# 3065PNPIMH register map
File version: 1.0
Registers are 32-bit, access per field, reset 0x0 unless marked. A register's access mark holds for its fields unless they carry their own. Offsets are from the block's base; [hi:lo] are bit positions.

## GPT0 — GPT0 peripheral interface
Base 0x14700000
Same registers: GPT1 0x14701000, GPT2 0x14702000, GPT3 0x14703000
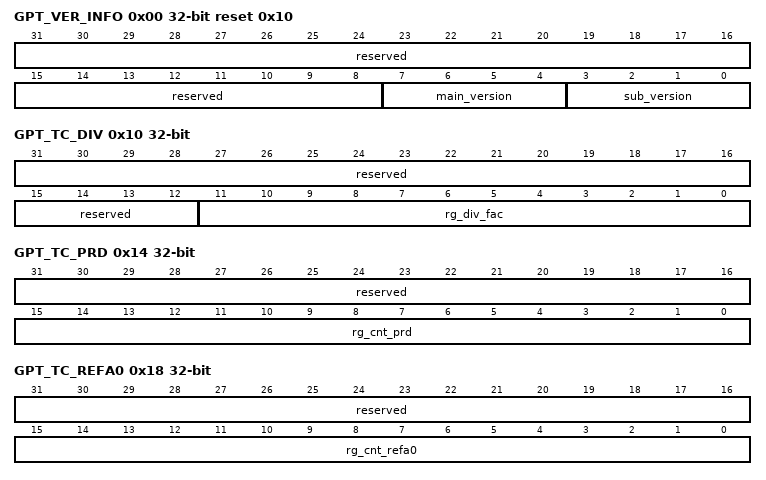
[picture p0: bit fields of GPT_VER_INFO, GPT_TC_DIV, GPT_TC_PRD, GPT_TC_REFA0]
0x00 GPT_VER_INFO ro reset 0x10 — GPT_VER_INFO为版本信息寄存器。
  [31:8] reserved — 保留。
  [7:4] main_version — 主版本号
  [3:0] sub_version — 子版本号
0x10 GPT_TC_DIV — GPT_TC_DIV为分频系数寄存器。
  [31:12] reserved ro — 保留。
  [11:0] rg_div_fac rw — 分频系数。 分频倍数=分频系数+1。
0x14 GPT_TC_PRD — GPT_TC_PRD为计数周期寄存器。
  [31:16] reserved ro — 保留。
  [15:0] rg_cnt_prd rw — 时基计数器（TCCNT）的计数周期。
0x18 GPT_TC_REFA0 — GPT_TC_REFA0为计数参考值A0寄存器。
  [31:16] reserved ro — 保留。
  [15:0] rg_cnt_refa0 rw — 时基计数器（TCCNT）的参考值A0，应当小于或等于计数周期。
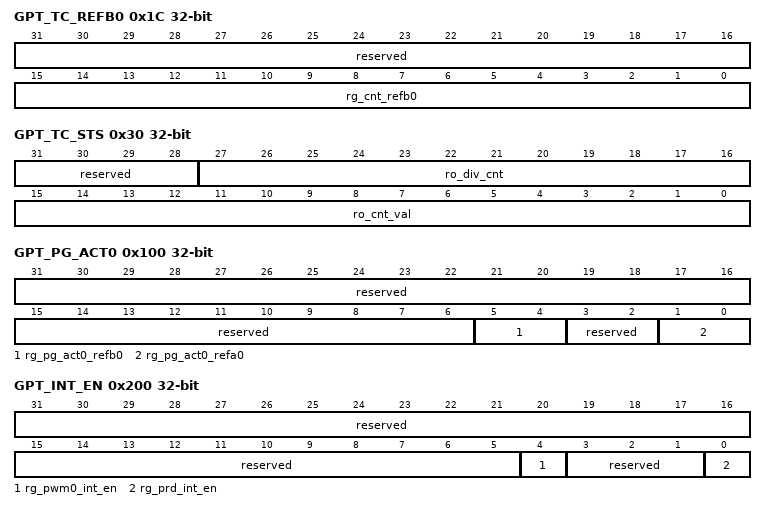
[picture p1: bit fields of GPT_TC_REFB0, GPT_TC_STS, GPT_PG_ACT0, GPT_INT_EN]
0x1C GPT_TC_REFB0 — GPT_TC_REFB0为计数参考值B0寄存器。
  [31:16] reserved ro — 保留。
  [15:0] rg_cnt_refb0 rw — 时基计数器（TCCNT）的参考值B0，应当小于或等于计数周期。
0x30 GPT_TC_STS ro — GPT_TC_STS为计数状态寄存器。
  [31:28] reserved — 保留。
  [27:16] ro_div_cnt — 分频计数器（DIVCNT）的当前计数值。
  [15:0] ro_cnt_val — 时基计数器（TCCNT）的当前计数值。
0x100 GPT_PG_ACT0 — GPT_PG_ACT0为通道0动作配置寄存器。
  [31:6] reserved ro — 保留。
  [5:4] rg_pg_act0_refb0 rw — 时基计数器（TCCNT）等于参考值B0时，通道0的PWM输出动作。 00：无影响； 01：置为低电平； 10：置为高电平； 11：翻转电平。
  [3:2] reserved ro — 保留。
  [1:0] rg_pg_act0_refa0 rw — 时基计数器（TCCNT）等于参考值A0时，通道0的PWM输出动作。 00：无影响； 01：置为低电平； 10：置为高电平； 11：翻转电平。
0x200 GPT_INT_EN — GPT_INT_EN为中断使能寄存器。
  [31:5] reserved ro — 保留。
  [4] rg_pwm0_int_en rw — 通道0输出完成中断的使能。 0：禁能； 1：使能。
  [3:1] reserved ro — 保留。
  [0] rg_prd_int_en rw — 周期中断的使能。 0：禁能； 1：使能。
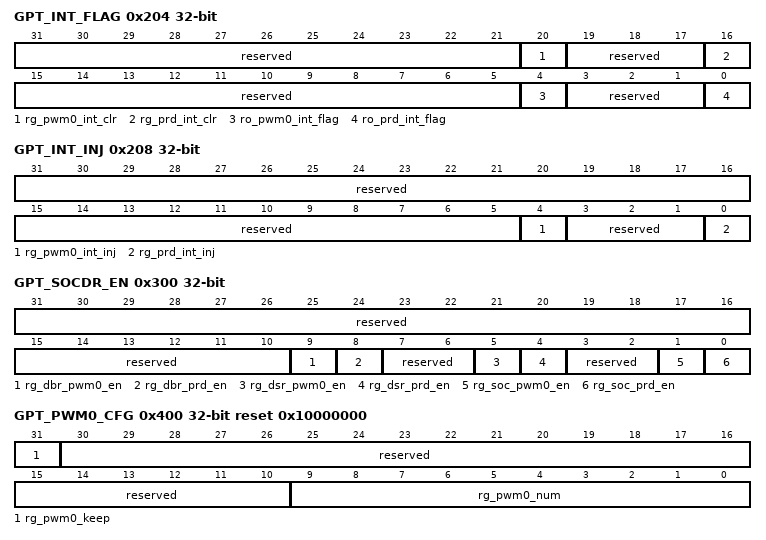
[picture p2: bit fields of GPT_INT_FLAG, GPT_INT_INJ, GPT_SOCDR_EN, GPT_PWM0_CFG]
0x204 GPT_INT_FLAG — GPT_INT_FLAG为中断标志寄存器。
  [31:21] reserved ro — 保留。
  [20] rg_pwm0_int_clr rw write-1-clears — 通道0输出完成中断的中断清除，写1清0。 0：写0无效； 1：写1有效。
  [19:17] reserved ro — 保留。
  [16] rg_prd_int_clr rw write-1-clears — 周期中断的中断清除，写1清0。 0：写0无效； 1：写1有效。
  [15:5] reserved ro — 保留。
  [4] ro_pwm0_int_flag ro — 通道0输出完成中断的中断标志。 0：通道0输出完成中断标志无效； 1：通道0输出完成中断标志有效。
  [3:1] reserved ro — 保留。
  [0] ro_prd_int_flag ro — 周期中断的中断标志。 0：周期中断标志无效； 1：周期中断标志有效。
0x208 GPT_INT_INJ — GPT_INT_INJ为中断注入寄存器。
  [31:5] reserved ro — 保留。
  [4] rg_pwm0_int_inj rw write-1-clears — 软件注入通道0输出完成中断，写1清0。 0：写0无效； 1：写1有效。
  [3:1] reserved ro — 保留。
  [0] rg_prd_int_inj rw write-1-clears — 软件注入周期中断，写1清0。 0：写0无效； 1：写1有效。
0x300 GPT_SOCDR_EN — GPT_SOCDR_EN为SOC/DMA请求使能寄存器。
  [31:10] reserved ro — 保留。
  [9] rg_dbr_pwm0_en rw — 通道0输出完成产生DMA Burst request信号的使能。 0：通道0输出完成时禁止产生DMA Burst request； 1：通道0输出完成时产生DMA Burst request信号。
  [8] rg_dbr_prd_en rw — 计数周期结束产生DMA Burst request信号的使能。 0：计数周期结束时禁止产生DMA Burst request； 1：计数周期结束时产生DMA Burst request信号。
  [7:6] reserved ro — 保留。
  [5] rg_dsr_pwm0_en rw — 通道0输出完成产生DMA Single request信号的使能。 0：通道0输出完成时禁止产生DMA Single request； 1：通道0输出完成时产生DMA Single request信号。
  [4] rg_dsr_prd_en rw — 计数周期结束产生DMA Single request信号的使能。 0：计数周期结束时禁止产生DMA Single request； 1：计数周期结束时产生DMA Single request信号。
  [3:2] reserved ro — 保留。
  [1] rg_soc_pwm0_en rw — 通道0输出完成产生SOC信号的使能。 0：通道0输出完成时禁止产生SOC信号； 1：通道0输出完成时产生SOC信号。
  [0] rg_soc_prd_en rw — 计数周期结束产生SOC信号的使能。 0：计数周期结束时禁止产生SOC信号； 1：计数周期结束时产生SOC信号。
0x400 GPT_PWM0_CFG reset 0x10000000 — GPT_PWM0_CFG为通道0配置寄存器。
  [31] rg_pwm0_keep rw — 通道0输出PWM的模式。 0：通道0输出有限个数PWM，输出个数由GPT_PWM0_CFG[rg_pwm0_num]配置； 1：通道0输出无限个数PWM。
  [30:10] reserved ro — 保留。
  [9:0] rg_pwm0_num rw — 通道0输出PWM的个数。 仅当GPT_PWM0_CFG[rg_pwm0_keep]为0时有效。
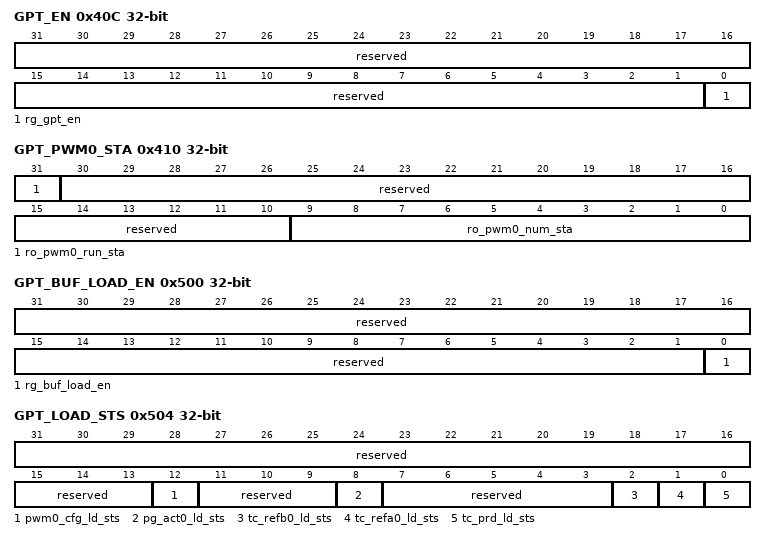
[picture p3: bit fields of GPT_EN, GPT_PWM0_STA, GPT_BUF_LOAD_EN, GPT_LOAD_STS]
0x40C GPT_EN — GPT_EN为GPT使能寄存器。
  [31:1] reserved ro — 保留。
  [0] rg_gpt_en rw — GPT使能控制。 0：GPT通道关闭； 1：GPT通道使能。
0x410 GPT_PWM0_STA ro — GPT_PWM0_STA为通道0状态寄存器。
  [31] ro_pwm0_run_sta — 通道0的输出状态。 0：表示目前通道0不在输出PWM波； 1：表示目前通道0正在输出PWM波。
  [30:10] reserved — 保留。
  [9:0] ro_pwm0_num_sta — 通道0输出PWM的个数。 当GPT_PWM0_CFG[rg_pwm0_keep]为1时，一直为0； 当GPT_PWM0_CFG[rg_pwm0_keep]为0时，GPT_PWM0_STA[ro_pwm0_num_sta]表示通道0正在输出第几个PWM波。
0x500 GPT_BUF_LOAD_EN — GPT_BUF_LOAD_EN为缓存加载使能寄存器。
  [31:1] reserved ro — 保留。
  [0] rg_buf_load_en rw — 支持缓存功能的寄存器的缓存加载使能。 0：禁能； 1：使能。
0x504 GPT_LOAD_STS ro — GPT_LOAD_STS为缓存加载状态寄存器。
  [31:13] reserved — 保留。
  [12] pwm0_cfg_ld_sts — 当使能了缓存加载功能，指示GPT_PWM0_CFG寄存器缓存的状态。 0：缓存寄存器空； 1：缓存寄存器满。
  [11:9] reserved — 保留。
  [8] pg_act0_ld_sts — 当使能了缓存加载功能，指示GPT_PG_ACT0寄存器缓存的状态。 0：缓存寄存器空； 1：缓存寄存器满。
  [7:3] reserved — 保留。
  [2] tc_refb0_ld_sts — 当使能了缓存加载功能，指示GPT_TC_REFB0寄存器缓存的状态。 0：缓存寄存器空； 1：缓存寄存器满。
  [1] tc_refa0_ld_sts — 当使能了缓存加载功能，指示GPT_TC_REFA0寄存器缓存的状态。 0：缓存寄存器空； 1：缓存寄存器满。
  [0] tc_prd_ld_sts — 当使能了缓存加载功能，指示GPT_TC_PRD寄存器缓存的状态。 0：缓存寄存器空； 1：缓存寄存器满。
